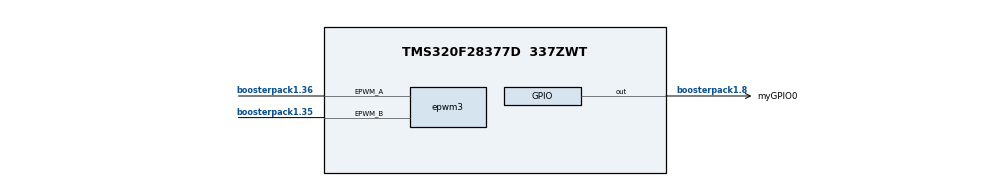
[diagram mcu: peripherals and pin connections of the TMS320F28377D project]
/**
 * These arguments were used when this file was generated. They will be automatically applied on subsequent loads
 * via the GUI or CLI. Run CLI with '--help' for additional information on how to override these arguments.
 * @cliArgs --board "/boards/LAUNCHXL_F28379D" --device "F2837xD" --part "F2837xD_337ZWT" --package "F2837xD_337ZWT" --context "CPU1" --product "C2000WARE@5.04.00.00"
 * @v2CliArgs --board "/boards/LAUNCHXL_F28379D" --device "TMS320F28377D" --package "337ZWT" --context "CPU1" --product "C2000WARE@5.04.00.00"
 * @versions {"tool":"1.22.0+3893"}
 */

/**
 * Import the modules used in this configuration.
 */
const adc       = scripting.addModule("/driverlib/adc.js", {}, false);
const adc1      = adc.addInstance();
const epwm      = scripting.addModule("/driverlib/epwm.js");
const epwm1     = epwm.addInstance();
const epwm2     = epwm.addInstance();
const epwm3     = epwm.addInstance();
const epwmxbar  = scripting.addModule("/driverlib/epwmxbar.js", {}, false);
const epwmxbar1 = epwmxbar.addInstance();
const gpio      = scripting.addModule("/driverlib/gpio.js", {}, false);
const gpio1     = gpio.addInstance();

/**
 * Write custom configuration values to the imported modules.
 */
adc1.$name                = "myADC0";
adc1.enabledSOCs          = ["ADC_SOC_NUMBER0"];
adc1.soc0InterruptTrigger = "ADC_INT_SOC_TRIGGER_ADCINT1";
adc1.soc0SampleWindow     = 20;
adc1.interruptPulseMode   = "ADC_PULSE_END_OF_CONV";
adc1.enabledInts          = ["ADC_INT_NUMBER1"];
adc1.enableInterrupt1     = true;
adc1.soc0Channel          = "ADC_CH_ADCIN1";
adc1.interrupt1SOCSource  = "ADC_SOC_NUMBER1";
adc1.adcClockPrescaler    = "ADC_CLK_DIV_4_0";

epwm.generateInitFunctions = true;

epwm1.$hardware                                        = system.deviceData.board.components.BP_SITE_1.subComponents.PWM_LOC1;
epwm1.$name                                            = "PhaseA";
epwm1.epwmActionQualifier_EPWM_AQ_OUTPUT_A_shadowMode  = true;
epwm1.epwmActionQualifier_EPWM_AQ_OUTPUT_B_shadowMode  = true;
epwm1.epwmActionQualifier_t2Source                     = "EPWM_AQ_TRIGGER_EVENT_TRIG_DCA_2";
epwm1.epwmDeadband_enableRED                           = true;
epwm1.epwmDeadband_enableFED                           = true;
epwm1.epwmEventTrigger_enableInterrupt                 = true;
epwm1.epwmEventTrigger_registerInterrupts              = true;
epwm1.epwmEventTrigger_interruptEventCount             = "1";
epwm1.epwmDeadband_polarityFED                         = "EPWM_DB_POLARITY_ACTIVE_LOW";
epwm1.epwmCounterCompare_cmpD                          = 5;
epwm1.epwmEventTrigger_interruptSource                 = "EPWM_INT_TBCTR_U_CMPC";
epwm1.epwmActionQualifier_continousSwForceReloadMode   = "EPWM_AQ_SW_SH_LOAD_ON_CNTR_PERIOD";
epwm1.epwmCounterCompare_shadowLoadModeCMPA            = "EPWM_COMP_LOAD_ON_CNTR_PERIOD";
epwm1.epwmCounterCompare_shadowLoadModeCMPB            = "EPWM_COMP_LOAD_ON_CNTR_PERIOD";
epwm1.epwmCounterCompare_shadowLoadModeCMPC            = "EPWM_COMP_LOAD_ON_CNTR_PERIOD";
epwm1.epwmCounterCompare_cmpC                          = 5;
epwm1.epwmCounterCompare_cmpA                          = 5;
epwm1.epwmCounterCompare_cmpB                          = 5;
epwm1.epwmTimebase_counterMode                         = "EPWM_COUNTER_MODE_UP";
epwm1.epwmActionQualifier_EPWM_AQ_OUTPUT_A_shadowEvent = "EPWM_AQ_LOAD_ON_CNTR_PERIOD";
epwm1.epwmActionQualifier_EPWM_AQ_OUTPUT_B_shadowEvent = "EPWM_AQ_LOAD_ON_CNTR_PERIOD";
epwm1.epwmDeadband_delayFED                            = 50;
epwm1.epwmDeadband_delayRED                            = 50;
epwm1.epwmTimebase_hsClockDiv                          = "EPWM_HSCLOCK_DIVIDER_10";
epwm1.epwmTimebase_clockDiv                            = "EPWM_CLOCK_DIVIDER_2";
epwm1.epwmTimebase_period                              = 250;
epwm1.epwmInt.enableInterrupt                          = true;

epwm2.epwmActionQualifier_EPWM_AQ_OUTPUT_A_shadowMode  = true;
epwm2.epwmActionQualifier_EPWM_AQ_OUTPUT_B_shadowMode  = true;
epwm2.epwmActionQualifier_t2Source                     = "EPWM_AQ_TRIGGER_EVENT_TRIG_DCA_2";
epwm2.epwmCounterCompare_cmpB                          = 1;
epwm2.epwmDeadband_enableRED                           = true;
epwm2.epwmDeadband_enableFED                           = true;
epwm2.epwmDeadband_polarityFED                         = "EPWM_DB_POLARITY_ACTIVE_LOW";
epwm2.$name                                            = "PhaseB";
epwm2.$hardware                                        = system.deviceData.board.components.BP_SITE_1.subComponents.PWM_LOC2;
epwm2.epwmTimebase_periodLink                          = "EPWM_LINK_WITH_EPWM_1";
epwm2.epwmActionQualifier_continousSwForceReloadMode   = "EPWM_AQ_SW_SH_LOAD_ON_CNTR_PERIOD";
epwm2.epwmCounterCompare_shadowLoadModeCMPA            = "EPWM_COMP_LOAD_ON_CNTR_PERIOD";
epwm2.epwmCounterCompare_shadowLoadModeCMPB            = "EPWM_COMP_LOAD_ON_CNTR_PERIOD";
epwm2.epwmCounterCompare_shadowLoadModeCMPC            = "EPWM_COMP_LOAD_ON_CNTR_PERIOD";
epwm2.epwmCounterCompare_cmpALink                      = "EPWM_LINK_WITH_EPWM_1";
epwm2.epwmCounterCompare_cmpBLink                      = "EPWM_LINK_WITH_EPWM_1";
epwm2.epwmCounterCompare_cmpCLink                      = "EPWM_LINK_WITH_EPWM_1";
epwm2.epwmCounterCompare_cmpA                          = 2;
epwm2.epwmTimebase_counterMode                         = "EPWM_COUNTER_MODE_UP";
epwm2.epwmActionQualifier_EPWM_AQ_OUTPUT_A_shadowEvent = "EPWM_AQ_LOAD_ON_CNTR_PERIOD";
epwm2.epwmActionQualifier_EPWM_AQ_OUTPUT_B_shadowEvent = "EPWM_AQ_LOAD_ON_CNTR_PERIOD";
epwm2.epwmDeadband_delayRED                            = 50;
epwm2.epwmDeadband_delayFED                            = 50;
epwm2.epwmTimebase_clockDiv                            = "EPWM_CLOCK_DIVIDER_2";
epwm2.epwmTimebase_hsClockDiv                          = "EPWM_HSCLOCK_DIVIDER_10";
epwm2.epwmTimebase_period                              = 250;

epwm3.epwmActionQualifier_EPWM_AQ_OUTPUT_A_shadowMode  = true;
epwm3.epwmActionQualifier_EPWM_AQ_OUTPUT_B_shadowMode  = true;
epwm3.epwmActionQualifier_t2Source                     = "EPWM_AQ_TRIGGER_EVENT_TRIG_DCA_2";
epwm3.epwmCounterCompare_cmpB                          = 1;
epwm3.epwmDeadband_enableRED                           = true;
epwm3.epwmDeadband_enableFED                           = true;
epwm3.epwmDeadband_polarityFED                         = "EPWM_DB_POLARITY_ACTIVE_LOW";
epwm3.$name                                            = "PhaseC";
epwm3.$hardware                                        = system.deviceData.board.components.BP_SITE_1.subComponents.PWM_LOC3;
epwm3.epwmTimebase_periodLink                          = "EPWM_LINK_WITH_EPWM_1";
epwm3.epwmCounterCompare_cmpALink                      = "EPWM_LINK_WITH_EPWM_1";
epwm3.epwmCounterCompare_shadowLoadModeCMPA            = "EPWM_COMP_LOAD_ON_CNTR_PERIOD";
epwm3.epwmCounterCompare_shadowLoadModeCMPB            = "EPWM_COMP_LOAD_ON_CNTR_PERIOD";
epwm3.epwmCounterCompare_cmpBLink                      = "EPWM_LINK_WITH_EPWM_1";
epwm3.epwmCounterCompare_shadowLoadModeCMPC            = "EPWM_COMP_LOAD_ON_CNTR_PERIOD";
epwm3.epwmCounterCompare_cmpCLink                      = "EPWM_LINK_WITH_EPWM_1";
epwm3.epwmTimebase_counterMode                         = "EPWM_COUNTER_MODE_UP";
epwm3.epwmActionQualifier_EPWM_AQ_OUTPUT_A_shadowEvent = "EPWM_AQ_LOAD_ON_CNTR_PERIOD";
epwm3.epwmActionQualifier_EPWM_AQ_OUTPUT_B_shadowEvent = "EPWM_AQ_LOAD_ON_CNTR_PERIOD";
epwm3.epwmDeadband_delayFED                            = 50;
epwm3.epwmDeadband_delayRED                            = 50;
epwm3.epwmTimebase_clockDiv                            = "EPWM_CLOCK_DIVIDER_2";
epwm3.epwmTimebase_hsClockDiv                          = "EPWM_HSCLOCK_DIVIDER_10";
epwm3.epwmTimebase_period                              = 250;
epwm3.epwm.$assign                                     = "EPWM3";
epwm3.epwm.epwm_aPin.$assign                           = "boosterpack1.36";
epwm3.epwm.epwm_bPin.$assign                           = "boosterpack1.35";

epwmxbar1.$name = "myEPWMXBAR0";

gpio1.$name             = "myGPIO0";
gpio1.direction         = "GPIO_DIR_MODE_OUT";
gpio1.writeInitialValue = true;
gpio1.gpioPin.$assign   = "boosterpack1.8";

/**
 * Pinmux solution for unlocked pins/peripherals. This ensures that minor changes to the automatic solver in a future
 * version of the tool will not impact the pinmux you originally saw.  These lines can be completely deleted in order to
 * re-solve from scratch.
 */
epwm1.epwm.$suggestSolution           = "EPWM1";
epwm1.epwm.epwm_aPin.$suggestSolution = "boosterpack1.40";
epwm1.epwm.epwm_bPin.$suggestSolution = "boosterpack1.39";
epwm2.epwm.$suggestSolution           = "EPWM2";
epwm2.epwm.epwm_aPin.$suggestSolution = "boosterpack1.38";
epwm2.epwm.epwm_bPin.$suggestSolution = "boosterpack1.37";
